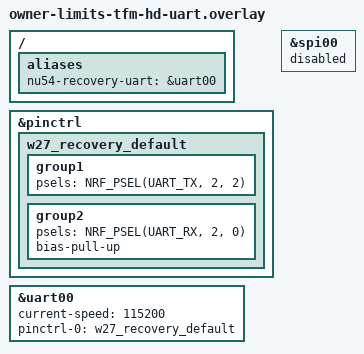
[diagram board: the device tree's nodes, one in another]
/* NU-54DK-C compile-only recovery accessory: P2 header, RX P2.00/TX P2.02.
 * VCOM1 remains on UARTE20 and the TF-M secure console remains on UARTE30. */
/ {
	aliases {
		nu54-recovery-uart = &uart00;
	};
};

&pinctrl {
	w27_recovery_default: w27_recovery_default {
		group1 {
			psels = <NRF_PSEL(UART_TX, 2, 2)>;
		};
		group2 {
			psels = <NRF_PSEL(UART_RX, 2, 0)>;
			bias-pull-up;
		};
	};
};

&spi00 {
	status = "disabled";
};

&uart00 {
	status = "okay";
	current-speed = <115200>;
	pinctrl-0 = <&w27_recovery_default>;
	pinctrl-names = "default";
};
